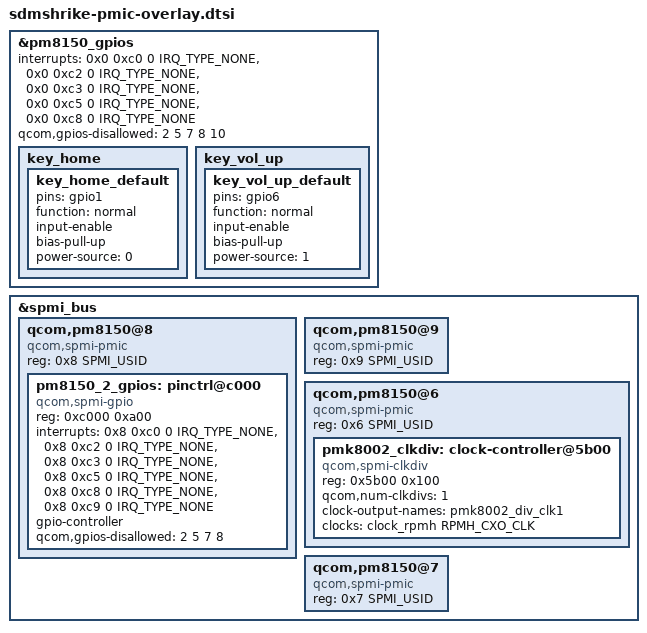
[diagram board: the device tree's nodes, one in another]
/*
 * Copyright (c) 2018, The Linux Foundation. All rights reserved.
 *
 * This program is free software; you can redistribute it and/or modify
 * it under the terms of the GNU General Public License version 2 and
 * only version 2 as published by the Free Software Foundation.
 *
 * This program is distributed in the hope that it will be useful,
 * but WITHOUT ANY WARRANTY; without even the implied warranty of
 * MERCHANTABILITY or FITNESS FOR A PARTICULAR PURPOSE.  See the
 * GNU General Public License for more details.
 */

#include "pm8150.dtsi"
#include "pm8150l.dtsi"

pm8150_1_gpios: &pm8150_gpios {
	interrupts = <0x0 0xc0 0 IRQ_TYPE_NONE>,
			<0x0 0xc2 0 IRQ_TYPE_NONE>,
			<0x0 0xc3 0 IRQ_TYPE_NONE>,
			<0x0 0xc5 0 IRQ_TYPE_NONE>,
			<0x0 0xc8 0 IRQ_TYPE_NONE>;
	interrupt-names = "pm8150_1_gpio1", "pm8150_1_gpio3",
			"pm8150_1_gpio4", "pm8150_1_gpio6",
			"pm8150_1_gpio9";
	qcom,gpios-disallowed = <2 5 7 8 10>;
};

/* PM8150_2: */
&spmi_bus {
	qcom,pm8150@8 {
		compatible = "qcom,spmi-pmic";
		reg = <0x8 SPMI_USID>;
		#address-cells = <1>;
		#size-cells = <1>;

		pm8150_2_gpios: pinctrl@c000 {
			compatible = "qcom,spmi-gpio";
			reg = <0xc000 0xa00>;
			interrupts = <0x8 0xc0 0 IRQ_TYPE_NONE>,
					<0x8 0xc2 0 IRQ_TYPE_NONE>,
					<0x8 0xc3 0 IRQ_TYPE_NONE>,
					<0x8 0xc5 0 IRQ_TYPE_NONE>,
					<0x8 0xc8 0 IRQ_TYPE_NONE>,
					<0x8 0xc9 0 IRQ_TYPE_NONE>;
			interrupt-names = "pm8150_2_gpio1", "pm8150_2_gpio3",
					"pm8150_2_gpio4", "pm8150_2_gpio6",
					"pm8150_2_gpio9", "pm8150_2_gpio10";
			gpio-controller;
			#gpio-cells = <2>;
			qcom,gpios-disallowed = <2 5 7 8>;
		};
	};

	qcom,pm8150@9 {
		compatible ="qcom,spmi-pmic";
		reg = <0x9 SPMI_USID>;
		#address-cells = <1>;
		#size-cells = <1>;
	};
};

/* PMK8002: */
&spmi_bus {
	qcom,pm8150@6 {
		compatible = "qcom,spmi-pmic";
		reg = <0x6 SPMI_USID>;
		#address-cells = <1>;
		#size-cells = <1>;

		pmk8002_clkdiv: clock-controller@5b00 {
			compatible = "qcom,spmi-clkdiv";
			reg = <0x5b00 0x100>;
			#clock-cells = <1>;
			qcom,num-clkdivs = <1>;
			clock-output-names = "pmk8002_div_clk1";
			clocks = <&clock_rpmh RPMH_CXO_CLK>;
			clock-names = "xo";
		};
	};

	qcom,pm8150@7 {
		compatible ="qcom,spmi-pmic";
		reg = <0x7 SPMI_USID>;
		#address-cells = <1>;
		#size-cells = <1>;
	};
};

/* PMIC GPIO pin control configurations: */
&pm8150_1_gpios {
	key_home {
		key_home_default: key_home_default {
			pins = "gpio1";
			function = "normal";
			input-enable;
			bias-pull-up;
			power-source = <0>;
		};
	};

	key_vol_up {
		key_vol_up_default: key_vol_up_default {
			pins = "gpio6";
			function = "normal";
			input-enable;
			bias-pull-up;
			power-source = <1>;
		};
	};
};
